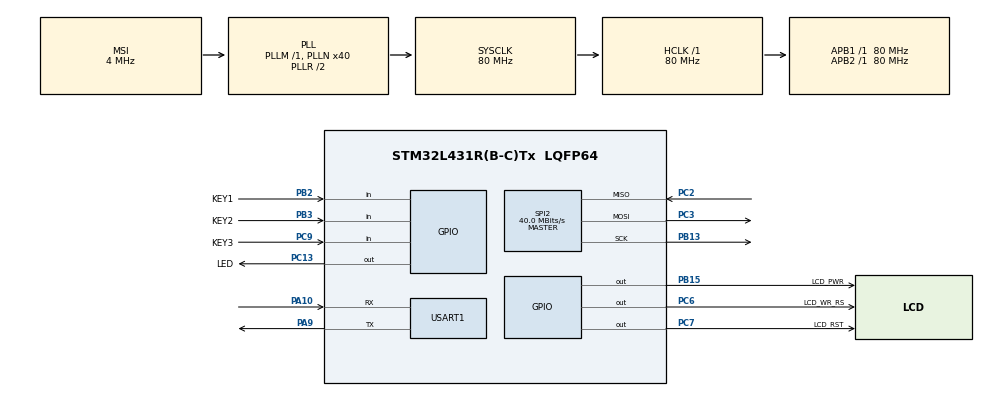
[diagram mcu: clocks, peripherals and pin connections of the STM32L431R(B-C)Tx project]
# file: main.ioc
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Mcu.Family=STM32L4
Mcu.Name=STM32L431R(B-C)Tx
Mcu.Package=LQFP64
NVIC.PriorityGroup=NVIC_PRIORITYGROUP_4
PA10.Mode=Asynchronous
PA10.Signal=USART1_RX
PA13\ (JTMS-SWDIO).Mode=Serial_Wire
PA13\ (JTMS-SWDIO).Signal=SYS_JTMS-SWDIO
PA14\ (JTCK-SWCLK).Mode=Serial_Wire
PA14\ (JTCK-SWCLK).Signal=SYS_JTCK-SWCLK
PA9.Mode=Asynchronous
PA9.Signal=USART1_TX
PB13.Mode=Full_Duplex_Master
PB13.Signal=SPI2_SCK
PB15.GPIO_Label=LCD_PWR
PB15.GPIO_Speed=GPIO_SPEED_FREQ_VERY_HIGH
PB15.Signal=GPIO_Output
PB2.GPIO_Label=KEY1
PB2.GPIO_PuPd=GPIO_PULLUP
PB2.Signal=GPIO_Input
PB3\ (JTDO-TRACESWO).GPIO_Label=KEY2
PB3\ (JTDO-TRACESWO).GPIO_PuPd=GPIO_PULLUP
PB3\ (JTDO-TRACESWO).Signal=GPIO_Input
PC13.GPIO_Label=LED
PC13.Signal=GPIO_Output
PC2.Mode=Full_Duplex_Master
PC2.Signal=SPI2_MISO
PC3.Mode=Full_Duplex_Master
PC3.Signal=SPI2_MOSI
PC6.GPIO_Label=LCD_WR_RS
PC6.GPIO_Speed=GPIO_SPEED_FREQ_VERY_HIGH
PC6.Signal=GPIO_Output
PC7.GPIO_Label=LCD_RST
PC7.GPIO_Speed=GPIO_SPEED_FREQ_VERY_HIGH
PC7.Signal=GPIO_Output
PC9.GPIO_Label=KEY3
PC9.GPIO_PuPd=GPIO_PULLUP
PC9.Signal=GPIO_Input
PH0-OSC_IN\ (PH0).Mode=HSE-External-Oscillator
PH0-OSC_IN\ (PH0).Signal=RCC_OSC_IN
PH1-OSC_OUT\ (PH1).Mode=HSE-External-Oscillator
PH1-OSC_OUT\ (PH1).Signal=RCC_OSC_OUT
ProjectManager.HeapSize=0x200
ProjectManager.StackSize=0x400
ProjectManager.TargetToolchain=MDK-ARM V5
RCC.AHBFreq_Value=80000000
RCC.APB1Freq_Value=80000000
RCC.APB1TimFreq_Value=80000000
RCC.APB2Freq_Value=80000000
RCC.APB2TimFreq_Value=80000000
RCC.CortexFreq_Value=80000000
RCC.HCLKFreq_Value=80000000
RCC.HSE_VALUE=8000000
RCC.HSI48_VALUE=48000000
RCC.HSI_VALUE=16000000
RCC.LSE_VALUE=32768
RCC.MSI_VALUE=4000000
RCC.PLLN=40
RCC.SYSCLKFreq_VALUE=80000000
RCC.SYSCLKSource=RCC_SYSCLKSOURCE_PLLCLK
RCC.VCOOutputFreq_Value=160000000
SPI2.CLKPhase=SPI_PHASE_2EDGE
SPI2.CLKPolarity=SPI_POLARITY_HIGH
SPI2.CalculateBaudRate=40.0 MBits/s
SPI2.DataSize=SPI_DATASIZE_8BIT
SPI2.Direction=SPI_DIRECTION_2LINES
SPI2.Mode=SPI_MODE_MASTER
SPI2.VirtualType=VM_MASTER
USART1.VirtualMode-Asynchronous=VM_ASYNC
VP_RTC_VS_RTC_Activate.Mode=RTC_Enabled
board=custom

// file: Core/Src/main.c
/* USER CODE BEGIN Header */
/**
  ******************************************************************************
  * @file           : main.c
  * @brief          : Main program body
  ******************************************************************************
  * @attention
  *
  * <h2><center>&copy; Copyright (c) 2020 STMicroelectronics.
  * All rights reserved.</center></h2>
  *
  * This software component is licensed by ST under BSD 3-Clause license,
  * the "License"; You may not use this file except in compliance with the
  * License. You may obtain a copy of the License at:
  *                        opensource.org/licenses/BSD-3-Clause
  *
  ******************************************************************************
  */
/* USER CODE END Header */
#include "main.h"
#include "rtc.h"
#include "spi.h"
#include "usart.h"
#include "gpio.h"

void SystemClock_Config(void);

int main(void)
{

  /* MCU Configuration--------------------------------------------------------*/

  /* Reset of all peripherals, Initializes the Flash interface and the Systick. */
  HAL_Init();

  /* Configure the system clock */
  SystemClock_Config();

  /* Initialize all configured peripherals */
  MX_GPIO_Init();
  MX_SPI2_Init();
  MX_USART1_UART_Init();
  MX_RTC_Init();
  /* USER CODE BEGIN 2 */
	LCD_Init();
	LCD_ShowChinese(0,0,(uint8_t *)"�о�԰����",WHITE,BLACK,12,1); //12*12
	LCD_ShowChinese(0,20,(uint8_t *)"�о�԰����",RED,BLACK,24,1); //24*24
	LCD_ShowChinese(0,60,(uint8_t *)"�о�԰����",YELLOW,BLACK,32,1); //32*32
	LCD_ShowChinese(0,100,(uint8_t *)"�о�԰����",GREEN,BLACK,48,1); //48*48
	LCD_ShowChinese(15,160,(uint8_t *)"�о�԰",BLUE,BLACK,64,1); //64*64
  /* USER CODE END 2 */

  /* Infinite loop */
  while (1)
  {

  }
}

void SystemClock_Config(void)
{
  RCC_OscInitTypeDef RCC_OscInitStruct = {0};
  RCC_ClkInitTypeDef RCC_ClkInitStruct = {0};
  RCC_PeriphCLKInitTypeDef PeriphClkInit = {0};

  /** Initializes the RCC Oscillators according to the specified parameters
  * in the RCC_OscInitTypeDef structure.
  */
  RCC_OscInitStruct.OscillatorType = RCC_OSCILLATORTYPE_LSI|RCC_OSCILLATORTYPE_MSI;
  RCC_OscInitStruct.LSIState = RCC_LSI_ON;
  RCC_OscInitStruct.MSIState = RCC_MSI_ON;
  RCC_OscInitStruct.MSICalibrationValue = 0;
  RCC_OscInitStruct.MSIClockRange = RCC_MSIRANGE_6;
  RCC_OscInitStruct.PLL.PLLState = RCC_PLL_ON;
  RCC_OscInitStruct.PLL.PLLSource = RCC_PLLSOURCE_MSI;
  RCC_OscInitStruct.PLL.PLLM = 1;
  RCC_OscInitStruct.PLL.PLLN = 40;
  RCC_OscInitStruct.PLL.PLLP = RCC_PLLP_DIV7;
  RCC_OscInitStruct.PLL.PLLQ = RCC_PLLQ_DIV2;
  RCC_OscInitStruct.PLL.PLLR = RCC_PLLR_DIV2;
  if (HAL_RCC_OscConfig(&RCC_OscInitStruct) != HAL_OK)
  {
    Error_Handler();
  }
  /** Initializes the CPU, AHB and APB buses clocks
  */
  RCC_ClkInitStruct.ClockType = RCC_CLOCKTYPE_HCLK|RCC_CLOCKTYPE_SYSCLK
                              |RCC_CLOCKTYPE_PCLK1|RCC_CLOCKTYPE_PCLK2;
  RCC_ClkInitStruct.SYSCLKSource = RCC_SYSCLKSOURCE_PLLCLK;
  RCC_ClkInitStruct.AHBCLKDivider = RCC_SYSCLK_DIV1;
  RCC_ClkInitStruct.APB1CLKDivider = RCC_HCLK_DIV1;
  RCC_ClkInitStruct.APB2CLKDivider = RCC_HCLK_DIV1;

  if (HAL_RCC_ClockConfig(&RCC_ClkInitStruct, FLASH_LATENCY_4) != HAL_OK)
  {
    Error_Handler();
  }
  PeriphClkInit.PeriphClockSelection = RCC_PERIPHCLK_RTC|RCC_PERIPHCLK_USART1;
  PeriphClkInit.Usart1ClockSelection = RCC_USART1CLKSOURCE_PCLK2;
  PeriphClkInit.RTCClockSelection = RCC_RTCCLKSOURCE_LSI;
  if (HAL_RCCEx_PeriphCLKConfig(&PeriphClkInit) != HAL_OK)
  {
    Error_Handler();
  }
  /** Configure the main internal regulator output voltage
  */
  if (HAL_PWREx_ControlVoltageScaling(PWR_REGULATOR_VOLTAGE_SCALE1) != HAL_OK)
  {
    Error_Handler();
  }
}

void Error_Handler(void)
{
}

/************************ (C) COPYRIGHT STMicroelectronics *****END OF FILE****/
